AUTOSAR XML (schema 4-2-2)
package /Components
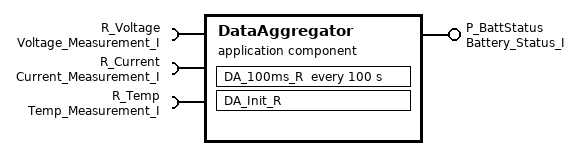
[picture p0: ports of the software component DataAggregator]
  application sw component type DataAggregator
    provide port P_BattStatus: provided-interface=Battery_Status_I
    require port R_Voltage: required-interface=Voltage_Measurement_I
    require port R_Current: required-interface=Current_Measurement_I
    require port R_Temp: required-interface=Temp_Measurement_I
    behavior DataAggregator_InternalBehavior
      init event DA_Init_Event: start-on-event=DA_Init_R
      timing event DA_100ms_Event: start-on-event=DA_100ms_R, period=100
      runnable DA_Init_R: symbol=DA_Init
        data-send-points:
          5 x access:
            VA_DA_Init_Tx_voltage: accessed-variable=P_BattStatus.voltage_mV
            VA_DA_Init_Tx_current: accessed-variable=P_BattStatus.current_mA
            VA_DA_Init_Tx_temp: accessed-variable=P_BattStatus.temp_cDegC
            VA_DA_Init_Tx_soc: accessed-variable=P_BattStatus.soc_perc
            VA_DA_Init_Tx_statusFlags: accessed-variable=P_BattStatus.status_flags
      runnable DA_100ms_R: minimum-start-interval=100, symbol=DA_100ms
        data-receive-point-by-values:
          access VA_DA_100ms_Rx_voltage: accessed-variable=R_Voltage.voltage_mV
          access VA_DA_100ms_Rx_current: accessed-variable=R_Current.current_mA
          access VA_DA_100ms_Rx_temp: accessed-variable=R_Temp.temp_cDegC
        data-send-points:
          5 x access:
            VA_DA_100ms_Tx_voltage: accessed-variable=P_BattStatus.voltage_mV
            VA_DA_100ms_Tx_current: accessed-variable=P_BattStatus.current_mA
            VA_DA_100ms_Tx_temp: accessed-variable=P_BattStatus.temp_cDegC
            VA_DA_100ms_Tx_soc: accessed-variable=P_BattStatus.soc_perc
            VA_DA_100ms_Tx_statusFlags: accessed-variable=P_BattStatus.status_flags
